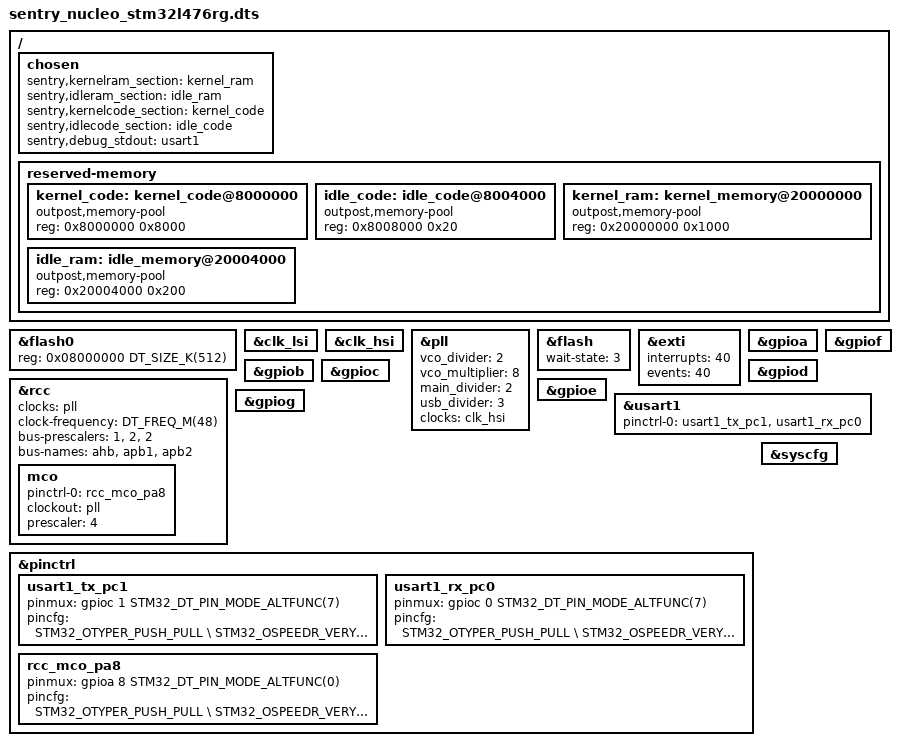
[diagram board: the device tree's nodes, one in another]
/*
 * Copyright (c) 2023,Ledger SAS
 *
 * SPDX-License-Identifier: Apache-2.0
 */

/dts-v1/;

#include <st/l4/stm32l476Xg.dtsi>
#include <dt-bindings/pinctrl/stm32-pinctrl.h>

/{
	chosen {
		sentry,kernelram_section = <&kernel_ram>;
		sentry,idleram_section = <&idle_ram>;
		sentry,kernelcode_section = <&kernel_code>;
		sentry,idlecode_section = <&idle_code>;
		sentry,debug_stdout = <&usart1>;
	};

	reserved-memory {
		#address-cells = <1>;
		#size-cells = <1>;

		kernel_code: kernel_code@8000000 {
        	reg = <0x8000000 0x8000>;
			compatible = "outpost,memory-pool";
    	};
		idle_code: idle_code@8004000 {
        	reg = <0x8008000 0x20>;
			compatible = "outpost,memory-pool";
    	};

		kernel_ram: kernel_memory@20000000 {
        	reg = <0x20000000 0x1000>;
			compatible = "outpost,memory-pool";
    	};

    	idle_ram: idle_memory@20004000 {
        	reg = <0x20004000 0x200>;
			compatible = "outpost,memory-pool";
    	};
	};
};

&flash0 {
	reg = <0x08000000 DT_SIZE_K(512)>;
};

&clk_lsi {
	status = "okay";
};

&clk_hsi {
	status = "okay";
};

&pll {
	vco_divider = <2>;
	vco_multiplier = <8>;
	main_divider = <2>;
	usb_divider = <3>;
	clocks = <&clk_hsi>;
	status = "okay";
};

&flash {
	wait-state = <3>; /* According to voltage supply and sysclock */
	status = "okay";
};

&exti {
	interrupts = <40>;
	events = <40>;
	status = "okay";
};

&rcc {
	clocks = <&pll>;
	clock-frequency = <DT_FREQ_M(48)>;
	bus-prescalers = <1>, <2>, <2>;
	bus-names = "ahb", "apb1", "apb2";
	status = "okay";

	mco {
		pinctrl-0 = <&rcc_mco_pa8>;
		clockout = <&pll>; /* XXX use reg value from svd */
		prescaler = <4>;
		status = "okay";
	};
};

&gpioa {
	status = "okay";
};

&gpiob {
	status = "okay";
};

&gpioc {
	status = "okay";
};

&gpiod {
	status = "okay";
};

&gpioe {
	status = "okay";
};

&gpiof {
	status = "okay";
};

&gpiog {
	status = "okay";
};

&usart1 {
    status = "okay";
	pinctrl-0 = <&usart1_tx_pc1>, <&usart1_rx_pc0>;
};

&pinctrl {
	usart1_tx_pc1: usart1_tx_pc1  {
		pinmux = <&gpioc 1 STM32_DT_PIN_MODE_ALTFUNC(7)>;
		pincfg = <STM32_OTYPER_PUSH_PULL \
				  STM32_OSPEEDR_VERY_HIGH_SPEED \
				  STM32_PUPDR_NO_PULL>;
	};

	usart1_rx_pc0: usart1_rx_pc0  {
		pinmux = <&gpioc 0 STM32_DT_PIN_MODE_ALTFUNC(7)>;
		pincfg = <STM32_OTYPER_PUSH_PULL \
				  STM32_OSPEEDR_VERY_HIGH_SPEED \
				  STM32_PUPDR_NO_PULL>;
	};

	rcc_mco_pa8: rcc_mco_pa8  {
		pinmux = <&gpioa 8 STM32_DT_PIN_MODE_ALTFUNC(0)>;
		pincfg = <STM32_OTYPER_PUSH_PULL \
				  STM32_OSPEEDR_VERY_HIGH_SPEED \
				  STM32_PUPDR_NO_PULL>;
	};
};

&syscfg {
	status = "okay";
};
